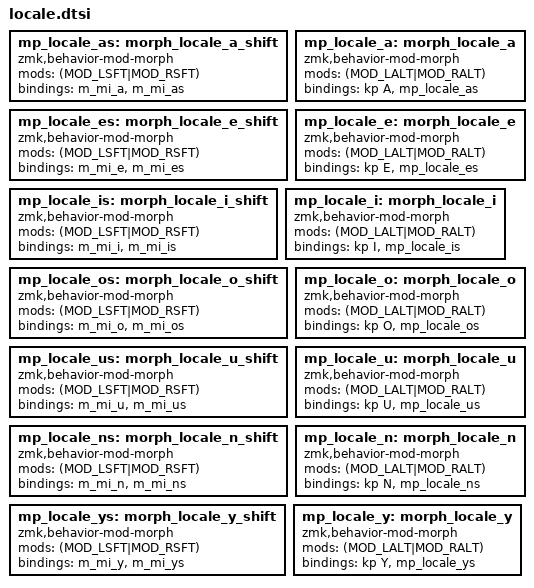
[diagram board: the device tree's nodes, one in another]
// tap:         a
// alt:         á
// alt+shift:   Á
mp_locale_as: morph_locale_a_shift {
    compatible = "zmk,behavior-mod-morph";
    #binding-cells = <0>;
    mods = <(MOD_LSFT|MOD_RSFT)>;
    bindings = <&m_mi_a>, <&m_mi_as>;
};
mp_locale_a: morph_locale_a {
    compatible = "zmk,behavior-mod-morph";
    #binding-cells = <0>;
    mods = <(MOD_LALT|MOD_RALT)>;
    bindings = <&kp A>, <&mp_locale_as>;
};

// tap:         e
// alt:         é
// alt+shift:   É
mp_locale_es: morph_locale_e_shift {
    compatible = "zmk,behavior-mod-morph";
    #binding-cells = <0>;
    mods = <(MOD_LSFT|MOD_RSFT)>;
    bindings = <&m_mi_e>, <&m_mi_es>;
};
mp_locale_e: morph_locale_e {
    compatible = "zmk,behavior-mod-morph";
    #binding-cells = <0>;
    mods = <(MOD_LALT|MOD_RALT)>;
    bindings = <&kp E>, <&mp_locale_es>;
};

// tap:         i
// alt:         í
// alt+shift:   Í
mp_locale_is: morph_locale_i_shift {
    compatible = "zmk,behavior-mod-morph";
    #binding-cells = <0>;
    mods = <(MOD_LSFT|MOD_RSFT)>;
    bindings = <&m_mi_i>, <&m_mi_is>;
};
mp_locale_i: morph_locale_i {
    compatible = "zmk,behavior-mod-morph";
    #binding-cells = <0>;
    mods = <(MOD_LALT|MOD_RALT)>;
    bindings = <&kp I>, <&mp_locale_is>;
};

// tap:         o
// alt:         ó
// alt+shift:   Ó
mp_locale_os: morph_locale_o_shift {
    compatible = "zmk,behavior-mod-morph";
    #binding-cells = <0>;
    mods = <(MOD_LSFT|MOD_RSFT)>;
    bindings = <&m_mi_o>, <&m_mi_os>;
};
mp_locale_o: morph_locale_o {
    compatible = "zmk,behavior-mod-morph";
    #binding-cells = <0>;
    mods = <(MOD_LALT|MOD_RALT)>;
    bindings = <&kp O>, <&mp_locale_os>;
};

// tap:         u
// alt:         ú
// alt+shift:   Ú
mp_locale_us: morph_locale_u_shift {
    compatible = "zmk,behavior-mod-morph";
    #binding-cells = <0>;
    mods = <(MOD_LSFT|MOD_RSFT)>;
    bindings = <&m_mi_u>, <&m_mi_us>;
};
mp_locale_u: morph_locale_u {
    compatible = "zmk,behavior-mod-morph";
    #binding-cells = <0>;
    mods = <(MOD_LALT|MOD_RALT)>;
    bindings = <&kp U>, <&mp_locale_us>;
};

// tap:         n
// alt:         ñ
// alt+shift:   Ñ
mp_locale_ns: morph_locale_n_shift {
    compatible = "zmk,behavior-mod-morph";
    #binding-cells = <0>;
    mods = <(MOD_LSFT|MOD_RSFT)>;
    bindings = <&m_mi_n>, <&m_mi_ns>;
};
mp_locale_n: morph_locale_n {
    compatible = "zmk,behavior-mod-morph";
    #binding-cells = <0>;
    mods = <(MOD_LALT|MOD_RALT)>;
    bindings = <&kp N>, <&mp_locale_ns>;
};

// tap:         y
// alt:         ü
// alt+shift:   Ü
mp_locale_ys: morph_locale_y_shift {
    compatible = "zmk,behavior-mod-morph";
    #binding-cells = <0>;
    mods = <(MOD_LSFT|MOD_RSFT)>;
    bindings = <&m_mi_y>, <&m_mi_ys>;
};
mp_locale_y: morph_locale_y {
    compatible = "zmk,behavior-mod-morph";
    #binding-cells = <0>;
    mods = <(MOD_LALT|MOD_RALT)>;
    bindings = <&kp Y>, <&mp_locale_ys>;
};

